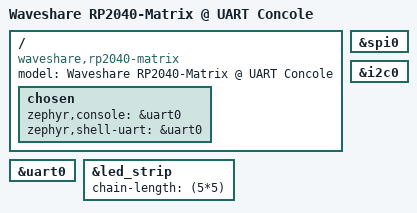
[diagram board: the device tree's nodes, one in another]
/*
 * Copyright (c) 2023 TiaC Systems
 * SPDX-License-Identifier: Apache-2.0
 */

/dts-v1/;

/ {
	model = "Waveshare RP2040-Matrix @ UART Concole";
	compatible = "waveshare,rp2040-matrix", "waveshare,rp2040-matrix-uartcons";

	chosen {
		zephyr,console = &uart0;
		zephyr,shell-uart = &uart0;
	};
};

#include "waveshare_rp2040-mini.dtsi"
#include "waveshare_rp2040-2mb.dtsi"

#include "rp2040mini_led_ws2812.dtsi"
#include "rp2040mini_connector.dtsi"

rp2040mini_serial: &uart0 {};
rp2040mini_spi: &spi0 {};
rp2040mini_i2c: &i2c0 {};

&led_strip {
	chain-length = <(5*5)>;
};

#include "waveshare_rp2040-mini-tweaks.dtsi"
